# AU302NDF51 register map
File version: 1.0
Registers are 32-bit, access per field, reset 0x0 unless marked. A register's access mark holds for its fields unless they carry their own. Offsets are from the block's base; [hi:lo] are bit positions; 'fields as' and 'values as' point back to an identical list.

## CAN
Base 0x14600000
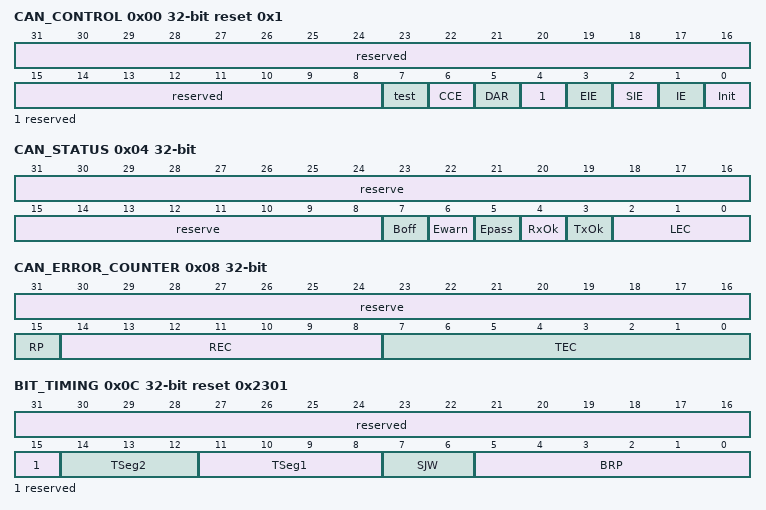
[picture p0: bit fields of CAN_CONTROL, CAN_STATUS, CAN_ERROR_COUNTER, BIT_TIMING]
0x00 CAN_CONTROL reset 0x1 — CAN_CONTROL 为 CAN控制寄存器
  [31:8] reserved ro — 保留
  [7] test rw — test mode使能。0:不使能；1：使能。
  [6] CCE rw — 更改配置使能。0：禁止， CPU 不能写 BIT_TIMING 寄存器；1：使能，当 Init 为 1 时， CPU 能写BIT_TIMING 寄存器。
  [5] DAR rw — 关闭自动重传。 0：开启自动重传受干扰的报文； 1：关闭自动重传。
  [4] reserved ro — 保留。
  [3] EIE rw — 错误中断使能。0：禁止；1：使能错误中断， CAN_STATUS 寄存器中的 boff 或 ewarn 变化时会产生中断。
  [2] SIE rw — 状态改变中断使能。0：禁止；1：使能状态改变中断，报文传输成功或检测到 CAN 总线错误时会产生中断。
  [1] IE rw — 模块中断使能。 0：禁止； 1：使能， CAN 模块中断总开关。
  [0] Init rw — 初始化使能。 0：禁止，此时 CAN 控制器处于正常工作 模式； 1：使能，此时 CAN 控制器处于初始化模 式。
0x04 CAN_STATUS — CAN_STATUS 为 CAN 状态寄存器
  [31:8] reserve ro — 保留。
  [7] Boff ro — Bus-off 状态。 0： CAN 模块不处于 bus-off 状态； 1： CAN 模块处于 bus-off 状态。
  [6] Ewarn ro — 警告状态。 0：所有错误计数器均未达到 96； 1：至少有一个错误计数器达到 96。
  [5] Epass ro — 错误状态。 0： 处于 CAN 协议所定义的主动错误； 1： 处于 CAN 协议所定义的被动错误。
  [4] RxOk rw — 报文接收状态。 0：接收报文失败； 1： 接收报文成功。
  [3] TxOk rw — 报文发送状态。 0：发送报文失败； 1：发送报文成功。
  [2:0] LEC rw — 错误状态码，用来表示 CAN 总线上最后一 次错误状态。 000：无错误； 001：填充错误； 010：形式错误； 011：应答错误； 100： bit1 错误； 101： bit0 错误； 110： CRC 错误； 111：保留。
0x08 CAN_ERROR_COUNTER ro — CAN_ERROR_COUNTER 为 CAN 错误计数寄存器。
  [31:16] reserve — 保留。
  [15] RP — 被动错误接收状态。 0：接收错误计数器未达到 CAN 协议所定 义的被动错误水线； 1： 接收错误计数器达到 CAN 协议所定义 的被动错误水线。
  [14:8] REC — 接收错误计数器。 有效值在 0~127。
  [7:0] TEC — 传输错误计数器。 有效值在 0~255。
0x0C BIT_TIMING reset 0x2301 — BIT_TIMING 为位时间寄存器。
  [31:15] reserved ro — 保留。
  [14:12] TSeg2 rw — 相位缓冲段 2。 配置值为 0~7， 实际值比配置值多 1。
  [11:8] TSeg1 rw — 相位缓冲段 1。 配置值为 1~15， 实际值比配置值多 1。
  [7:6] SJW rw — 再同步跳转宽度。 配置值为 0~3， 实际值比配置值多 1。
  [5:0] BRP rw — 波特率系数。 配置值为 0~63， 实际值比配置值多 1。
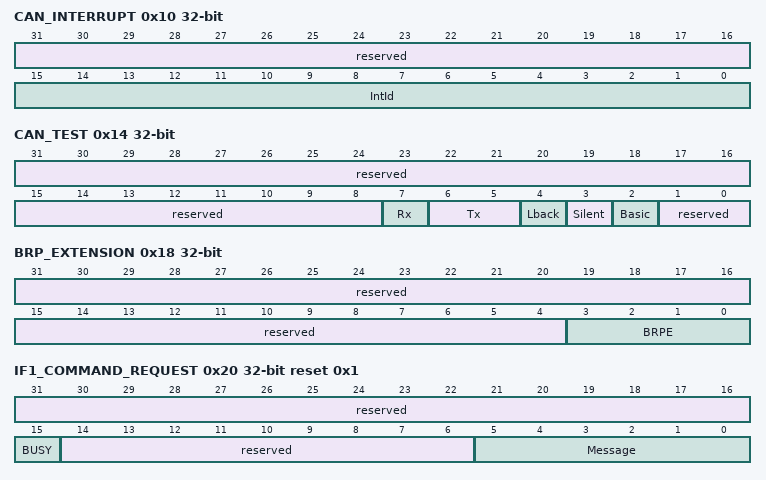
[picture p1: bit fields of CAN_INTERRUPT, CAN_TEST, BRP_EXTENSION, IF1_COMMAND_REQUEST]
0x10 CAN_INTERRUPT — CAN_INTERRUPT 为 CAN 中断寄存器。
  [31:16] reserved ro — 保留。
  [15:0] IntId rw — 中断 ID。 0x0000：无中断； 0x0001：中断源是第 1 个报文对象； 0x0002：中断源是第 2 个报文对象； 0x0003：中断源是第 3 个报文对象； 0x0004：中断源是第 4 个报文对象； 0x0005：中断源是第 5 个报文对象； 0x0006：中断源是第 6 个报文对象； 0x0007：中断源是第 7 个报文对象； 0x0008：中断源是第 8 个报文对象； 0x0009：中断源是第 9 个报文对象； 0x000A：中断源是第 10 个报文对象； 0x000B：中断源是第 11 个报文对象； 0x000C：中断源是第 12 个报文对象； 0x000D：中断源是第 13 个报文对象； 0x000E：中断源是第 14 个报文对象； 0x000F：中断源是第 15 个报文对象； 0x0010：中断源是第 16 个报文对象； 0x0011：中断源是第 17 个报文对象； 0x0012：中断源是第 18 个报文对象； 0x0013：中断源是第 19 个报文对象； 0x0014：中断源是第 20 个报文对象； 0x0015：中断源是第 21 个报文对象； 0x0016：中断源是第 22 个报文对象； 0x0017：中断源是第 23 个报文对象； 0x0018：中断源是第 24 个报文对象； 0x0019：中断源是第 25 个报文对象； 0x001A：中断源是第 26 个报文对象； 0x001B：中断源是第 27 个报文对象； 0x001C：中断源是第 28 个报文对象； 0x001D：中断源是第 29 个报文对象； 0x001E：中断源是第 30 个报文对象； 0x001F：中断源是第 31 个报文对象； 0x0020：中断源是第 32 个报文对象； 0x0021-0x7FFF：无效； 0x8000：状态中断； 0x8001-0xFFFF：无效。
0x14 CAN_TEST — CAN_TEST 为 CAN 调试寄存器。
  [31:8] reserved ro — 保留。
  [7] Rx rw — CAN_RX 管脚监控。 0： CAN 总线为显性（CAN_RX=’0’） ；1： CAN 总线为隐形（CAN_RX=’1’） 。
  [6:5] Tx ro — CAN_TX 管脚控制。 00： 不控制 CAN_TX 管脚； 01：采样点能被 CAN_TX 管脚监视； 10： CAN_TX 管脚驱动显性值（'0’） ； 11： CAN_TX 管脚驱动隐形值（'1’） 。
  [4] Lback rw — Loop back 模式使能。 0：禁止； 1：使能。
  [3] Silent rw — Silent 模式使能。 0：禁止； 1：使能。
  [2] Basic rw — Basic 模式使能。 0：禁止； 1：使能，此时 IF1 寄存器用作 Tx Buffer， IF2 寄存器用作 Rx Buffer。
  [1:0] reserved ro — 保留。
0x18 BRP_EXTENSION — BRP_EXTENSION 为 BRP 扩展寄存器。
  [31:4] reserved ro — 保留。
  [3:0] BRPE rw — 波特率系数扩展。扩展后的波特率系数有 brpe 和 brp 共同组成，其中 brpe 构成 MSBs， brp 构成LSBs。
0x20 IF1_COMMAND_REQUEST reset 0x1 — IF1_COMMAND_REQUEST 为 IF1 命令请求寄存器。
  [31:16] reserved ro — 保留。
  [15] BUSY rw — Busy 标志。 0： IF1 命令已经完成； 1： IF1 命令执行中。
  [14:6] reserved ro — 保留。
  [5:0] Message Number rw — 报文对象序号。 CPU 写该位域后， IF1 命 令开始执行。 0x00：无效值，将指向 0x20； 0x01~0x20：报文对象序号； 0x21-0x3F：无效值，将指向 0x01- 0x1F。 其他： 保留。
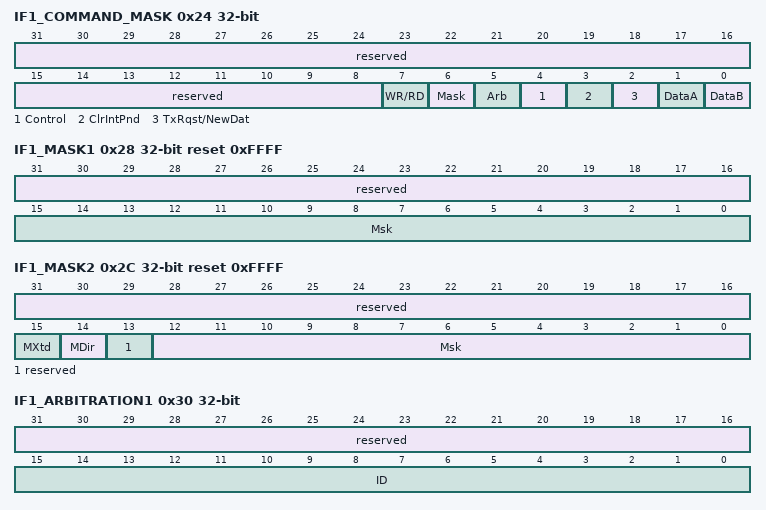
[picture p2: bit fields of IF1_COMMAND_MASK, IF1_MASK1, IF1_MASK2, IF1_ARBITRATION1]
0x24 IF1_COMMAND_MASK — IF1_COMMAND_MASK 为 IF1 命令掩码寄存器。
  [31:8] reserved ro — 保留。
  [7] WR/RD rw — 读写命令， 控制 IF1 报文缓冲寄存器和 Message RAM 传输方向。0： 读命令，将 Message RAM 中存储的 报文对象回读到 IF1 报文缓冲寄存器； 1： 写命令，将 IF1 报文缓冲寄存器写入到 Message RAM 中存储的报文对象。
  [6] Mask rw — 命令掩码，控制 IF1_MASK 的传输。 当 WR/RD 寄存器为 1， 写命令时：0：不写入， 报文对象的 ID Mask、 Mdir、MXtd 不改变； 1：将 IF1_MASK1 和 IF1_MASK2 寄存器中的ID Mask、 Mdir、 MXtd 写入报文对象。当 WR/RD 寄存器为 0， 读命令时： 0：不回读， IF1_MASK 不改变；1：将报文对象的 ID Mask、 Mdir、 MXtd 回读到 IF1_MASK1 和 IF1_MASK2 寄存器中。
  [5] Arb rw — 命令掩码，控制 IF1_ARBITRATION 的传输。当 WR/RD 寄存器为 1， 写命令时： 0： 不写入， 报文对象的 ID、 Dir、 Xtd、MsgVal 不改变；1：将 IF1_ARBITRATION1 和IF1_ARBITRATION2 中的 ID、 Dir、 Xtd、 MsgVal 位写入报文对象。当 WR/RD 寄存器为 0， 读命令时：0：不回读， IF1_ARBITRATION 不改 变；1：将报文对象的 ID、 Dir、 Xtd、 MsgVal回读到 IF1_ARBITRATION1 和IF1_ARBITRATION2 寄存器中。
  [4] Control rw — 命令掩码，控制 IF1_MESSAGE_CONTROL 的传输。 当 WR/RD 寄存器为 1， 写命令时： 0： 不写入， 报文对象中的 IF1_MESSAGE_CONTROL 相关比特位 不改变； 1：将 IF1_MESSAGE_CONTROL 的比特 位写入报文对象。 当 WR/RD 寄存器为 0， 读命令时： 0：不回读， IF1_MESSAGE_CONTROL 不改变； 1：将报文对象中的相应比特位回读到 IF1_MESSAGE_CONTROL 寄存器中。
  [3] ClrIntPnd rw — 命令掩码，清除报文对象的中断待处理。 当 WR/RD 寄存器为 1，写命令时： 该位域忽略。 当 WR/RD 寄存器为 0，读命令时： 0： 报文对象的 IntPnd 位保持不变； 1：清除报文对象的 IntPnd 位。
  [2] TxRqst/NewDat rw — 命令掩码， 控制报文对象的 TxRqst 位或 者 NewDat 位。 当 WR/RD 寄存器为 1 时，写命令时： 访问 TxRqst 位。 0： 将 IF1_MESSAGE_CONTROL 寄存器 的 TxRqst 位写入报文对象； 1： 忽略 IF1_MESSAGE_CONTROL 寄存 器的 TxRqst 位。 直接置位报文对象的 TxRqst 位，请求报文发送。 当 WR/RD 寄存器为 0 时，读命令时：访问 NewDat 位， IF1_MESSAGE_CONTROL 寄存器的 NewData 位不会被更新。 0： 报文对象的 NewDat 位均保持不变； 1：清除报文对象的 NewDat 位。
  [1] DataA rw — 命令掩码，控制 IF1_DATAA 的传输。 当 WR/RD 寄存器为 1 时，写命令时： 0：报文对象中的数据 Byte 0-3 保持不 变； 1：将 IF1_DATAA 寄存器写入报文对象， 更新报文对象中的数据 Byte 0-3。 当 WR/RD 寄存器为 0 时，读命令时： 0： IF1_DATAA 寄存器保持不变； 1： 将报文对象中的数据 Byte 0-3 回读到 IF1_DATAA 寄存器中。
  [0] DataB rw — 命令掩码，控制 IF1_DATAB 的传输。 当 WR/RD 寄存器为 1 时，写命令时： 0：报文对象中的数据 Byte 4-7 保持不 变； 1：将 IF1_DATAB 寄存器写入报文对象， 更新报文对象中的数据 Byte 4~7。 当 WR/RD 寄存器为 0 时，读命令时： 0： IF1_DATAB 寄存器保持不变； 1： 将报文对象中的数据 Byte 4-7 回读到 IF1_DATAB 寄存器中。
0x28 IF1_MASK1 reset 0xFFFF — IF1_MASK1 为 IF1 掩码寄存器 1。
  [31:16] reserved ro — 保留。
  [15:0] Msk rw — 报文对象 ID 第 15 位至第 0 位掩码，用于 报文接收过滤。 0： ID 第 15 位至第 0 位不用于报文接收过 滤； 1： ID 第 15 位至第 0 位用于报文接收过 滤。
0x2C IF1_MASK2 reset 0xFFFF — IF1_MASK2 为 IF1 掩码寄存器 2。
  [31:16] reserved ro — 保留。
  [15] MXtd rw — 报文对象的拓展 ID 位（Xtd）掩码，用于 接收报文过滤。 0： Xtd 不用于报文接收过滤； 1： Xtd 用于报文接收过滤。
  [14] MDir rw — 报文对象的方向位（Dir）掩码，用于接收 报文过滤。 0： Dir 不用于报文接收过滤； 1： Dir 用于报文接收过滤。
  [13] reserved ro — 保留。
  [12:0] Msk rw — 报文对象 ID 第 28 位至第 16 位掩码，用于 接收报文过滤。0： ID 第 28 位至第 16 位不用于报文接收过滤；1： ID 第 28 位至第 16 位用于报文接收过滤。
0x30 IF1_ARBITRATION1 — IF1_ARBITRATION1 为 IF1 仲裁寄存器 1。
  [31:16] reserved ro — 保留。
  [15:0] ID rw — 报文对象的报文 ID 第 15 位至第 0 位。 注意：当报文对象用于收发扩展帧时，应使用全部 ID；当报文对象用于收发标准帧时，应使用 ID的高 11 位。
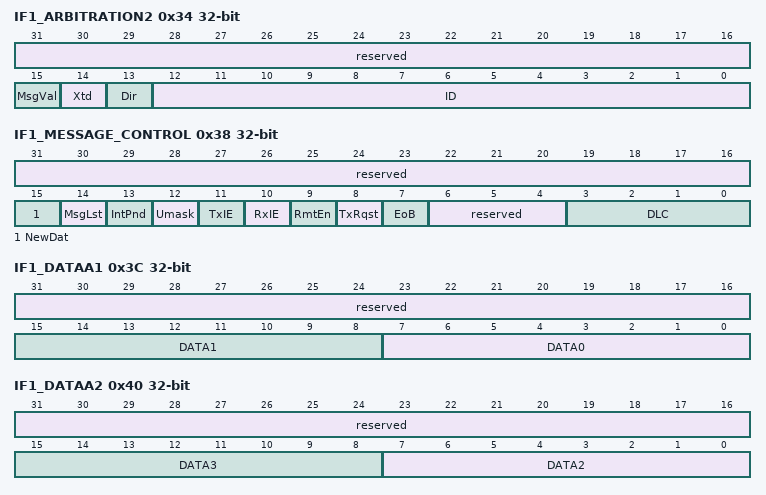
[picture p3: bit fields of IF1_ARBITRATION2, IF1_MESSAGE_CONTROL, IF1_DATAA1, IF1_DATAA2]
0x34 IF1_ARBITRATION2 — IF1_ARBITRATION2 为 IF1 仲裁寄存器 2。
  [31:16] reserved ro — 保留。
  [15] MsgVal rw — 报文对象有效使能。 0：禁止，该报文对象无效； 1：使能，该报文对象有效。
  [14] Xtd rw — 报文对象收发帧格式。 0：该报文对象收发标准格式帧； 1：该报文对象收发扩展格式帧。
  [13] Dir rw — 报文对象的方向。 0： 报文对象为接收方向， 接收报文； 1： 报文对象为发送方向， 发送报文。
  [12:0] ID rw — 报文对象的报文 ID 第 28 位至第 16 位。 注意：当报文对象用于收发扩展帧时，应使用全部 ID；当报文对象用于收发标准帧时，应使用 ID的高 11 位。
0x38 IF1_MESSAGE_CONTROL — IF1_MESSAGE_CONTROL 为 IF1 报文控制寄存器。
  [31:16] reserved ro — 保留。
  [15] NewDat rw — 报文对象的新数据写入状态。 报文对象为发送方向时： 0：无新的帧数据写入报文对象，报文对象 成功发送后会清除报文对象中的 newdat； 1：有新的帧数据写入报文对象。 报文对象为接收方向时： 0：报文对象没有接收到新的帧； 1：报文对象接收到了新的帧。
  [14] MsgLst rw — 报文对象的报文丢失标识（仅在报文对象 为接收方向时有效） 。 0： 报文对象无报文丢失； 1： 报文对象有报文丢失，当报文对象的 newdat 位未被清除，新的报文已接收时， 报文对象的 msglst 置 1。
  [13] IntPnd rw — 报文对象的中断待处理标识。 0：该报文对象不是中断源；1：该报文对象是中断源。
  [12] Umask rw — 报文对象是否使用报文掩码，用于报文接 收过滤。 0：不使用； 1： 使用相关掩码位（Msk28-0， MXtd 和 Mdir） 用于报文接收过滤。
  [11] TxIE rw — 发送中断使能。 0： 不使能，帧发送成功后 intpnd 保持不 变； 1： 使能，帧发送成功后 intpnd 将被置1。
  [10] RxIE rw — 接收中断使能。 0： 不使能，帧接收成功后 intpnd 保持不 变； 1： 使能， 帧接收成功后 intpnd 将被置1。
  [9] RmtEn rw — 远程帧使能。 0： 不使能， 接收远程帧后 TxRqst 保持不 变； 1： 使能， 接收远程帧后 TxRqst 置 1。
  [8] TxRqst rw — 传输请求。 0：该报文对象没在等待传输； 1：该报文对象请求传输，并且还没传输完 成。
  [7] EoB rw — 多报文接收模式。 0：该报文对象不是多报文接收模式中最后 一个报文对象； 1：该报文对象是单一报文或是多报文接收 模式中最后一个报文对象。
  [6:4] reserved ro — 保留。
  [3:0] DLC rw — 数据长度编码。0x0-0x8：数据帧有 0-8 个数据字节； 0x9~0xF：数据帧有 8 个数据字节。
0x3C IF1_DATAA1 — IF1_DATAA1 为 IF1 数据 A1 寄存器。
  [31:16] reserved ro — 保留。
  [15:8] DATA1 rw — CAN 帧数据 Byte 1
  [7:0] DATA0 rw — CAN 帧数据 Byte 0。
0x40 IF1_DATAA2 — IF1_DATAA2 为 IF1 数据 A2 寄存器。
  [31:16] reserved ro — 保留。
  [15:8] DATA3 rw — CAN 帧数据 Byte 3。
  [7:0] DATA2 rw — CAN 帧数据 Byte 2。
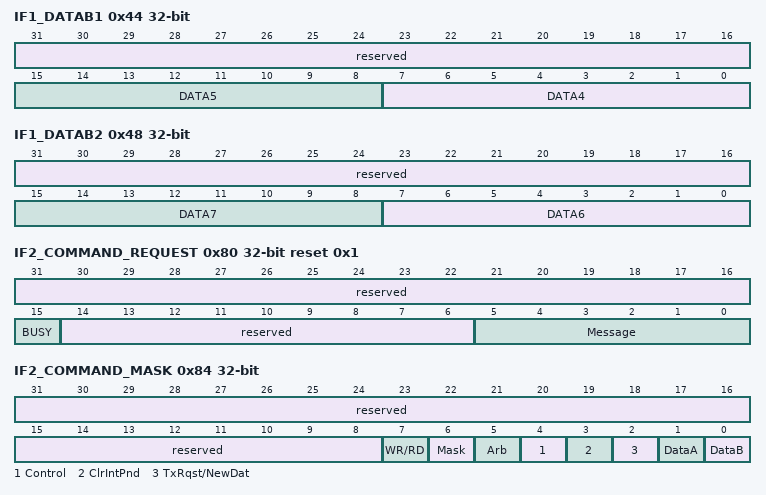
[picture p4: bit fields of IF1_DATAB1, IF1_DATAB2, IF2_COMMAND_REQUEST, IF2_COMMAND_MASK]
0x44 IF1_DATAB1 — IF1_DATAB1 为 IF1 数据 B1 寄存器。
  [31:16] reserved ro — 保留。
  [15:8] DATA5 rw — CAN 帧数据 Byte 5。
  [7:0] DATA4 rw — CAN 帧数据 Byte 4。
0x48 IF1_DATAB2 — IF1_DATAB2 为 IF1 数据 B2 寄存器。
  [31:16] reserved ro — 保留。
  [15:8] DATA7 rw — CAN 帧数据 Byte 7。
  [7:0] DATA6 rw — CAN 帧数据 Byte 6。
0x80 IF2_COMMAND_REQUEST reset 0x1 — IF2_COMMAND_REQUEST 为 IF2 命令请求寄存器。
  [31:16] reserved ro — 保留。
  [15] BUSY rw — busy 标志。 0： IF2 命令已经完成； 1： IF2 命令执行中。
  [14:6] reserved ro — 保留。
  [5:0] Message Number rw — 报文对象序号。 CPU 写该位域后， IF2 命 令开始执行。 0x00：无效值，将指向 0x20； 0x01~0x20：报文对象序号； 0x21-0x3F：无效值，将指向 0x01-0x1F。
0x84 IF2_COMMAND_MASK — IF2_COMMAND_MASK 为 IF2 命令掩码寄存器。
  [31:8] reserved ro — 保留。
  [7] WR/RD rw — 读写命令， 控制 IF2 报文缓冲寄存器和 message ram 传输方向。 0： 读命令，将 message ram 中存储的报 文对象回读到 IF2 报文缓冲寄存器； 1： 写命令，将 IF2 报文缓冲寄存器写入到 message ram 中存储的报文对象。
  [6] Mask rw — 命令掩码，控制 IF2_MASK 的传输。 当 wr/rd 寄存器为 1， 写命令时：0：不写入， 报文对象的 id mask、 mdir、mxtd 不改变； 1：将 IF2_MASK1 和 IF2_MASK2 寄存器中的 id mask、 mdir、 mxtd 写入报文对象。 当 wr/rd 寄存器为 0， 读命令时：0：不回读， IF2_MASK 不改变；1：将报文对象的 id mask、 mdir、 mxtd 回 读到 IF2_MASK1 和 IF2_MASK2 寄存器中。
  [5] Arb rw — 命令掩码，控制 IF2_ARBITRATION 的传 输。 当 WR/RD 寄存器为 1， 写命令时： 0： 不写入， 报文对象的 id、 dir、 xtd、 msgval 不改变； 1：将 IF2_ARBITRATION1 和 IF2_ARBITRATION2 中的 ID、 dir、 xtd、 msgval 位写入报文对象。 当 WR/RD 寄存器为 0， 读命令时：0：不回读， IF2_ ARBITRATION 不改 变； 1：将报文对象的 ID、 dir、 xtd、 msgVal 回读到 IF2_ARBITRATION1 和 IF2_ARBITRATION2 寄存器中。
  [4] Control rw — 命令掩码，控制 IF2_MESSAGE_CONTROL 的传输。 当 WR/RD 寄存器为 1， 写命令时： 0： 不写入， 报文对象中的IF2_MESSAGE_CONTROL 相关比特位不改变； 1：将 IF2_MESSAGE_CONTROL 的比特位写入报文对象。当 WR/RD 寄存器为 0， 读命令时： 0：不回读， IF2_MESSAGE_CONTROL不改变；1：将报文对象中的相应比特位回读到IF2_MESSAGE_CONTROL 寄存器中。
  [3] ClrIntPnd rw — 命令掩码，清除报文对象的中断待处理。 当 WR/RD 寄存器为 1，写命令时： 该位域忽略。 当 WR/RD 寄存器为 0，读命令时： 0： 报文对象的 IntPnd 位保持不变； 1：清除报文对象的 IntPnd 位。
  [2] TxRqst/NewDat rw — 命令掩码， 控制报文对象的 TxRqst 位或者NewDat 位。 当 WR/RD 寄存器为 1 时，写命令时： 访问 TxRqst 位。 0：报文对象 TxRqst 位保持不变； 1：置位报文对象的 TxRqst 位，请求报文发送。 当 WR/RD 寄存器为 0 时，读命令时： 访问 NewDat 位。 0：报文对象的 NewDat 位保持不变； 1：清除报文对象的 NewDat 位。
  [1] DataA rw — 命令掩码，控制 IF2_DATAA 的传输。 当 WR/RD 寄存器为 1 时，写命令时： 0：报文对象中的数据 Byte 0-3 保持不 变； 1：将 IF2_DATAA 寄存器写入报文对象， 更新报文对象中的数据 Byte 0-3。 当 WR/RD 寄存器为 0 时，读命令时： 0： IF2_DATAA 寄存器保持不变； 1： 将报文对象中的数据 Byte 0-3 回读到 IF2_DATAA 寄存器中。
  [0] DataB rw — 命令掩码，控制 IF2_DATAB 的传输。 当 WR/RD 寄存器为 1 时，写命令时： 0：报文对象中的数据 Byte 4-7 保持不 变； 1：将 IF2_DATAB 寄存器写入报文对象， 更新报文对象中的数据 Byte 4-7。 当 WR/RD 寄存器为 0 时，读命令时： 0： IF2_DATAB 寄存器保持不变； 1： 将报文对象中的数据 Byte 4-7 回读到 IF2_DATAB 寄存器中。
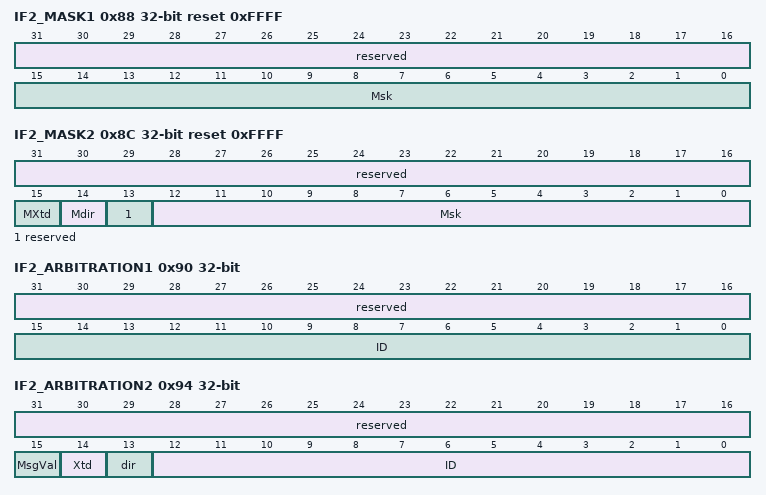
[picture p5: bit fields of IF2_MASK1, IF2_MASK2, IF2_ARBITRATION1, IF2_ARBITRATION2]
0x88 IF2_MASK1 reset 0xFFFF — IF2_MASK1 为 IF2 掩码寄存器 1。
  fields as IF1_MASK1
0x8C IF2_MASK2 reset 0xFFFF — IF2_MASK2 为 IF2 掩码寄存器 2。
  [31:16] reserved ro — 保留。
  [15] MXtd rw — 报文对象的拓展 ID 位（xtd）掩码，用于 报文接收过滤。 0： xtd 不用于报文接收过滤； 1： xtd 用于报文接收过滤。
  [14] Mdir rw — 报文对象的方向位（dir）掩码，用于报文 接收过滤。 0： dir 不用于报文接收过滤； 1： dir 用于报文接收过滤。
  [13] reserved ro — 保留。
  [12:0] Msk rw — 报文对象 ID 第 28 位至第 16 位掩码，用于 报文接收过滤。0： ID 第 28 位至第 16 位不用于报文接收过滤；1： ID 第 28 位至第 16 位用于报文接收过滤。
0x90 IF2_ARBITRATION1 — IF2_ARBITRATION1 为 IF2 仲裁寄存器 1。
  [31:16] reserved ro — 保留。
  [15:0] ID rw — 报文对象的报文 ID 第 15 位至第 0 位。 注意： 当报文对象用于收发扩展帧时，应使用全 部 ID； 当报文对象用于收发标准帧时，应使用 ID 的高 11 位。
0x94 IF2_ARBITRATION2 — IF2_ARBITRATION2 为 IF2 仲裁寄存器 2。
  [31:16] reserved ro — 保留。
  [15] MsgVal rw — 报文对象有效使能。 0：禁止，该报文对象无效； 1：使能，该报文对象有效。
  [14] Xtd rw — 报文对象收发帧格式。 0：该报文对象收发标准格式帧； 1：该报文对象收发扩展格式帧。
  [13] dir rw — 报文对象的方向。 0： 报文对象为接收方向， 接收报文；1： 报文对象为发送方向， 发送报文。
  [12:0] ID rw — 报文对象的报文 ID 第 28 位至第 16 位。 注意： 当报文对象用于收发扩展帧时，应使用全 部 ID； 当报文对象用于收发标准帧时，应使用 ID 的高 11 位。
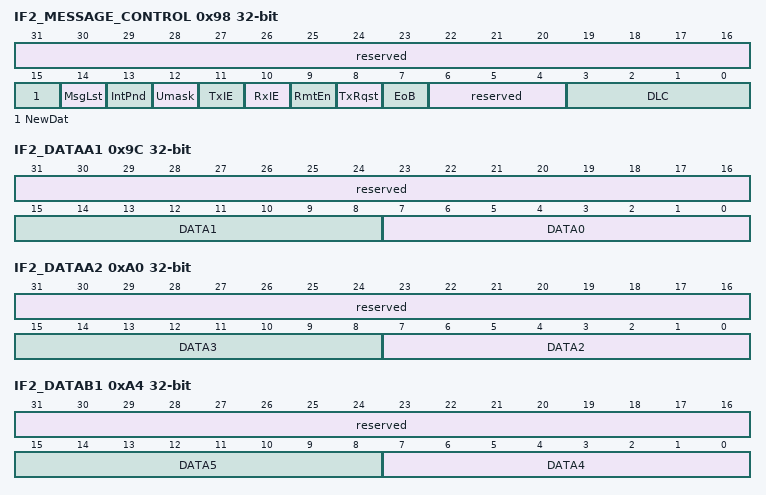
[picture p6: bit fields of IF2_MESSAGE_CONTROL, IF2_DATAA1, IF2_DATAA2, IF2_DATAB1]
0x98 IF2_MESSAGE_CONTROL — IF2_MESSAGE_CONTROL 为 IF2 报文控制寄存器。
  [31:16] reserved ro — 保留。
  [15] NewDat rw — 报文对象的帧数据标识。 报文对象为发送方向时： 0：无新的帧数据写入报文对象，报文对象 成功发送后会清除报文对象中的 newdat； 1：有新的帧数据写入报文对象。 报文对象为接收方向时： 0：报文对象没有接收到新的帧； 1：报文对象接收到了新的帧。
  [14] MsgLst rw — 报文对象的报文丢失标识（仅在报文对象 为接收方向时有效） 。 0： 报文对象无报文丢失； 1： 报文对象有报文丢失，当报文对象的 newdat 位未被清除，新的报文已接收时， 报文对象的 msglst 置 1。
  [13] IntPnd rw — 报文对象的中断待处理标识。0：该报文对象不是中断源； 1：该报文对象是中断源。
  [12] Umask rw — 报文对象是否使用报文掩码，用于报文接 收过滤。 0：不使用； 1： 使用相关掩码位（msk28-0， mxtd 和 mdir） 用于报文接收过滤。
  [11] TxIE rw — 发送中断使能。 0： 不使能，帧发送成功后 intpnd 保持不 变； 1： 使能，帧发送成功后 intPnd 将被置1。
  [10] RxIE rw — 接收中断使能。 0： 不使能，帧接收成功后 intpnd 保持不 变； 1： 使能， 帧接收成功后 intpnd 将被置1。
  [9] RmtEn rw — 远程帧使能。 0： 不使能， 接收远程帧后 TxRqst 保持不 变； 1： 使能， 接收远程帧后 TxRqst 置 1。
  [8] TxRqst rw — 传输请求。 0：该报文对象没在等待传输； 1：该报文对象请求传输，并且还没传输完 成。
  [7] EoB rw — 多报文接收模式。 0：该报文对象不是多报文接收模式中最后 一个报文对象； 1：该报文对象是单一报文或是多报文接收 模式中最后一个报文对象。
  [6:4] reserved ro — 保留。
  [3:0] DLC rw — 数据长度编码。 0x0-0x8：数据帧有 0-8 个数据字节； 0x9-0xF：数据帧有 8 个数据字节。
0x9C IF2_DATAA1 — IF2_DATAA1 为 IF2 数据 A1 寄存器。
  [31:16] reserved ro — 保留。
  [15:8] DATA1 rw — CAN 帧数据 Byte 1。
  [7:0] DATA0 rw — CAN 帧数据 Byte 0。
0xA0 IF2_DATAA2 — IF2_DATAA2 为 IF2 数据 A2 寄存器。
  fields as IF1_DATAA2
0xA4 IF2_DATAB1 — IF2_DATAB1 为 IF2 数据 B1 寄存器。
  fields as IF1_DATAB1
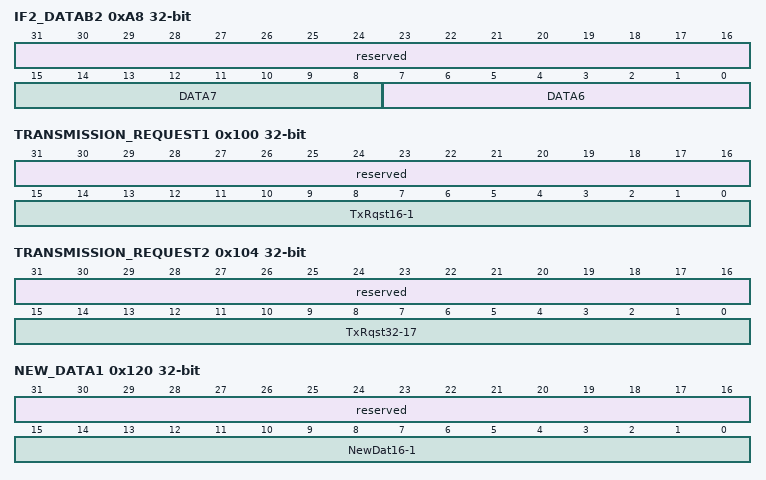
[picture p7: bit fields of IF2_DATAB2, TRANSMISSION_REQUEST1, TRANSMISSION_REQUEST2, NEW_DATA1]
0xA8 IF2_DATAB2 — IF2_DATAB2 为 IF2 数据 B2 寄存器。
  fields as IF1_DATAB2
0x100 TRANSMISSION_REQUEST1 ro — TRANSMISSION_REQUEST1 为传输请求状态寄存器 1。
  [31:16] reserved — 保留。
  [15:0] TxRqst16-1 — 传输请求状态（TxRqst16-1 每 bit 分别对 应报文对象 16-1） 。 CPU 可以回读检查传 输请求中的报文对象。 CPU 可以通过 IF 报文对象接口寄存器组， 配置报文对象发 出传输请求。 0：该报文对象没有等待传输； 1：该报文对象请求发送，并且还没传输完 成。
0x104 TRANSMISSION_REQUEST2 ro — TRANSMISSION_REQUEST2 为传输请求状态寄存器 2。
  [31:16] reserved — 保留。
  [15:0] TxRqst32-17 — 传输请求状态（TxRqst32-17 每 bit 分别对 应报文对象 32-17） 。 CPU 可以回读检查 传输请求中的报文对象。 CPU 可以通过 IF 报文对象接口寄存器组， 配置报文对象发 出传输请求。 0：该报文对象没有等待传输； 1：该报文对象请求发送，并且还没传输完 成。
0x120 NEW_DATA1 ro — NEW_DATA1 为新数据状态寄存器 1。
  [31:16] reserved — 保留。
  [15:0] NewDat16-1 — 新数据写入状态（newdat16-1 每 bit 分别 对应报文对象 16-1） 。 CPU 可以回读检查 报文对象是否接收到新的数据帧。 CPU 可 以通过 IF 报文对象接口寄存器组， 配置报 文对象 newdat 位域置位或清零。 CAN 控 制器的报文对象在接收报文成功后， 相应 的 newdat 自动置位。 0：无新数据写入该报文对象； 1：有新数据写入该报文对象。
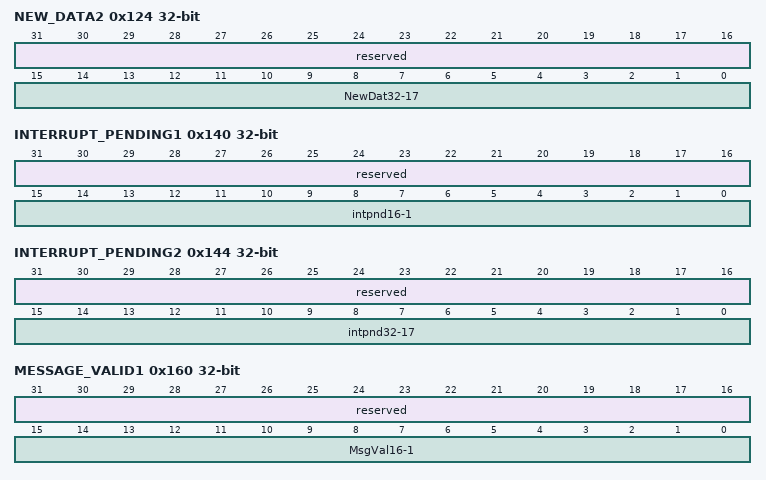
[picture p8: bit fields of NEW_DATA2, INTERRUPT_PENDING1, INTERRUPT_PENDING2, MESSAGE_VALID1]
0x124 NEW_DATA2 ro — NEW_DATA2 为新数据状态寄存器 2。
  [31:16] reserved — 保留。
  [15:0] NewDat32-17 — 新数据写入状态（newdat32-17 每 bit 分别 对应报文对象 32-17） 。 CPU 可以回读检 查报文对象是否接收到新的数据帧。 CPU 可以通过 IF 报文对象接口寄存器组， 配置 报文对象 newdat 位域置位或清零。 CAN 控制器的报文对象在接收报文成功后， 相 应的 newdat 自动置位。 0：无新数据写入该报文对象； 1：有新数据写入该报文对象。
0x140 INTERRUPT_PENDING1 ro — INTERRUPT_PENDING1 为中断待处理状态寄存器 1。
  [31:16] reserved — 保留。
  [15:0] intpnd16-1 — 中断待处理状态（intpnd16-1 每 bit 分别对 应报文对象 16-1） 。 CPU 可以回读检查报 文对象是否是中断源。 CPU 可以通过 IF 报文对象接口寄存器组， 配置报文对象 intpnd 位域置位或清零。 CAN 控制器的报 文对象在接收报文成功后，或者发送报文 成功后，相应的 intpnd 自动置位。 0：该报文对象不是中断源； 1：该报文对象是中断源。
0x144 INTERRUPT_PENDING2 ro — INTERRUPT_PENDING2 为中断待处理状态寄存器 2。
  [31:16] reserved — 保留。
  [15:0] intpnd32-17 — 中断待处理状态（intpnd32-17 每 bit 分别 对应报文对象 32-17） 。 CPU 可以回读检 查报文对象是否是中断源。 CPU 可以通过 IF 报文对象接口寄存器组， 配置报文对象 intpnd 位域置位或清零。 CAN 控制器的报 文对象在接收报文成功后，或者发送报文 成功后，相应的 intpnd 自动置位。 0：该报文对象不是中断源； 1：该报文对象是中断源。
0x160 MESSAGE_VALID1 ro — MESSAGE_VALID1 为报文有效状态寄存器 1。
  [31:16] reserved — 保留。
  [15:0] MsgVal16-1 — 报文对象有效状态（msgval16-1 每 bit 分 别对应报文对象 16-1） 。 CPU 可以回读检 查报文对象是否有效。 CPU 可以通过 IF 报文对象接口寄存器组， 配置报文对象 msgval 位域置位或清零。 0：该报文对象无效； 1：该报文对象有效。
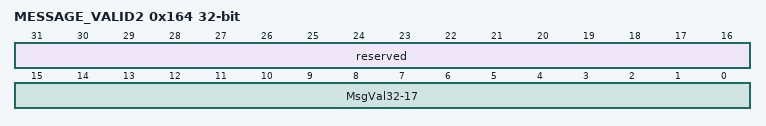
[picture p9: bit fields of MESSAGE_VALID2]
0x164 MESSAGE_VALID2 ro — MESSAGE_VALID2 为报文有效状态寄存器 2。
  [31:16] reserved — 保留。
  [15:0] MsgVal32-17 — 报文对象有效状态（msgval32-17 每 bit 分 别对应报文对象 32-17） 。 CPU 可以回读 检查报文对象是否有效。 CPU 可以通过 IF 报文对象接口寄存器组， 配置报文对象 msgval 位域置位或清零。 0：该报文对象无效； 1：该报文对象有效。
